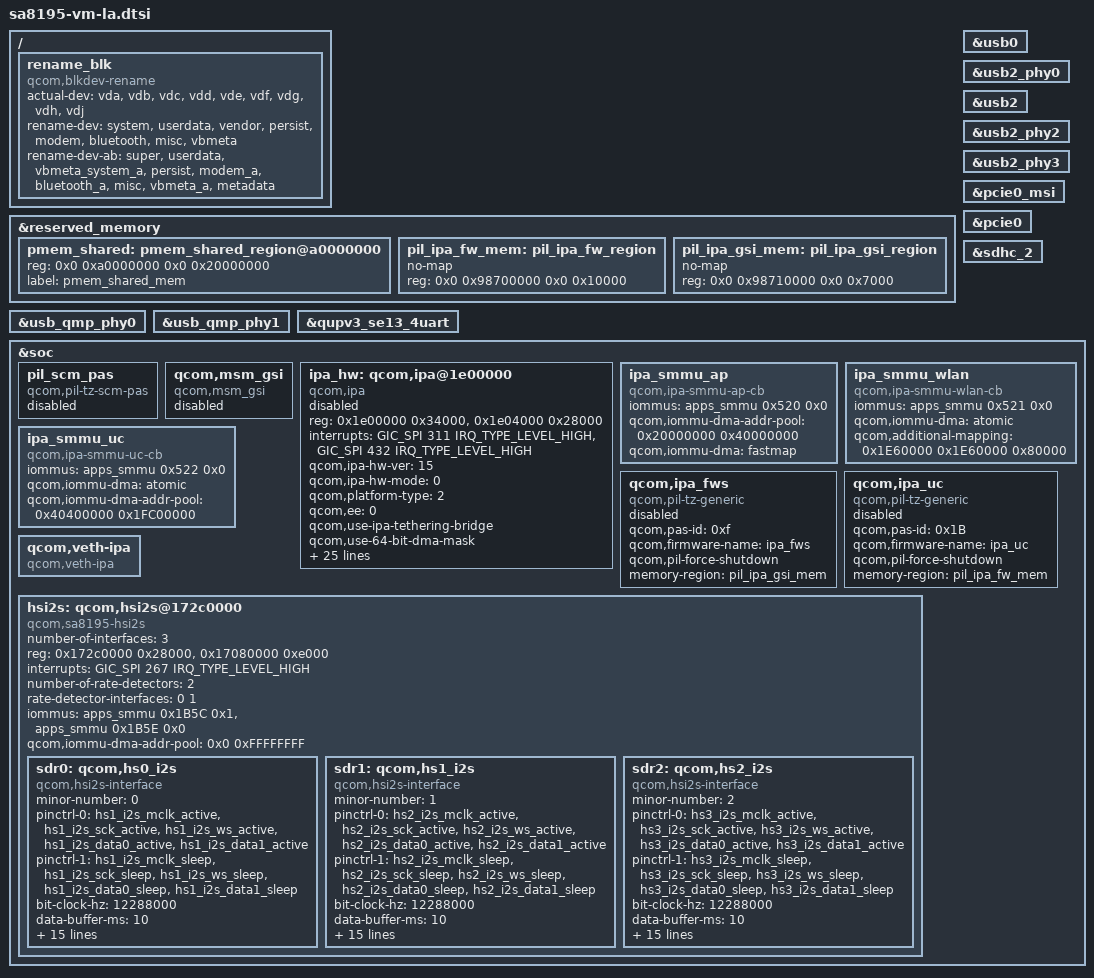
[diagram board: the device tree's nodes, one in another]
&reserved_memory {
	pmem_shared: pmem_shared_region@a0000000 {
		reg = <0x0 0xa0000000 0x0 0x20000000>;
		label = "pmem_shared_mem";
	};

	pil_ipa_fw_mem: pil_ipa_fw_region {
		no-map;
		reg = <0x0 0x98700000 0x0 0x10000>;
	};

	pil_ipa_gsi_mem: pil_ipa_gsi_region {
		no-map;
		reg = <0x0 0x98710000 0x0 0x7000>;
	};

};

/ {
	rename_blk: rename_blk {
		compatible = "qcom,blkdev-rename";
		actual-dev = "vda", "vdb", "vdc",
				"vdd", "vde", "vdf",
				"vdg", "vdh", "vdj";
		rename-dev = "system", "userdata", "vendor",
				"persist", "modem", "bluetooth",
				"misc", "vbmeta";
		rename-dev-ab = "super", "userdata", "vbmeta_system_a",
				"persist", "modem_a", "bluetooth_a",
				"misc", "vbmeta_a", "metadata";
	};
};

#include "display/quin-vm-display-la.dtsi"

&usb0 {
	status = "ok";
};

&usb2_phy0 {
	status = "ok";
};

&usb2 {
	status = "ok";
};

&usb2_phy2 {
	status = "ok";
};

&usb_qmp_phy0 {
	status = "ok";
};

&usb2_phy3 {
	status = "ok";
};

&usb_qmp_phy1 {
	status = "ok";
};

&qupv3_se13_4uart {
	status = "ok";
};

&pcie0_msi {
	status = "ok";
};

&pcie0 {
	status = "ok";
};

&sdhc_2 {
	status = "ok";
};
&soc {
	pil_scm_pas {
		compatible = "qcom,pil-tz-scm-pas";
		status = "disabled";
	};

	qcom,msm_gsi {
		compatible = "qcom,msm_gsi";
		status = "disabled";
	};

	ipa_hw: qcom,ipa@1e00000 {
		compatible = "qcom,ipa";
		reg = <0x1e00000 0x34000>,
			  <0x1e04000 0x28000>;
		reg-names = "ipa-base", "gsi-base";
		interrupts =
			<GIC_SPI 311 IRQ_TYPE_LEVEL_HIGH>,
			<GIC_SPI 432 IRQ_TYPE_LEVEL_HIGH>;
		interrupt-names = "ipa-irq", "gsi-irq";
		qcom,ipa-hw-ver = <15>; /* IPA core version = IPAv4.1 */
		qcom,ipa-hw-mode = <0>;
		qcom,platform-type = <2>; /* APQ platform */
		qcom,ee = <0>;
		qcom,use-ipa-tethering-bridge;
		qcom,use-64-bit-dma-mask;
		qcom,arm-smmu;
		qcom,use-ipa-pm;
		qcom,ipa-config-is-auto;
		qcom,bandwidth-vote-for-ipa;
		qcom,ipa-wdi3-over-gsi;
		qcom,manual-fw-load;
		qcom,lan-rx-napi;
		qcom,tx-wrapper-cache-max-size = <400>;
		qcom,tx-napi;
		qcom,max_num_smmu_cb = <3>;
		qcom,register-collection-on-crash;
		qcom,testbus-collection-on-crash;
		qcom,non-tn-collection-on-crash;
		qcom,interconnect,num-cases = <5>;
		qcom,interconnect,num-paths = <0>;
		interconnects = <>;
		/* No vote */
		qcom,no-vote = <>;

		/* SVS2 */
		qcom,svs2 = <>;

		/* SVS */
		qcom,svs = <>;

		/* NOMINAL */
		qcom,nominal = <>;

		/* TURBO */
		qcom,turbo = <>;

		qcom,bus-vector-names = "MIN", "SVS2", "SVS", "NOMINAL",
		"TURBO";
		qcom,throughput-threshold = <310 600 1000>;
		qcom,scaling-exceptions = <>;
		status = "disabled";
	};

	ipa_smmu_ap: ipa_smmu_ap {
		compatible = "qcom,ipa-smmu-ap-cb";
		iommus = <&apps_smmu 0x520 0x0>;
		qcom,iommu-dma-addr-pool = <0x20000000 0x40000000>;
		qcom,iommu-dma = "fastmap";
	};

	ipa_smmu_wlan: ipa_smmu_wlan {
		compatible = "qcom,ipa-smmu-wlan-cb";
		iommus = <&apps_smmu 0x521 0x0>;
		qcom,iommu-dma = "atomic";
		qcom,additional-mapping =
		/* ipa-uc ram */
		<0x1E60000 0x1E60000 0x80000>;
	};

	ipa_smmu_uc: ipa_smmu_uc {
		compatible = "qcom,ipa-smmu-uc-cb";
		iommus = <&apps_smmu 0x522 0x0>;
		qcom,iommu-dma = "atomic";
		qcom,iommu-dma-addr-pool = <0x40400000 0x1FC00000>;
	};

	qcom,ipa_fws {
		compatible = "qcom,pil-tz-generic";
		qcom,pas-id = <0xf>;
		qcom,firmware-name = "ipa_fws";
		qcom,pil-force-shutdown;
		memory-region = <&pil_ipa_gsi_mem>;
		status = "disabled";
	};

	qcom,ipa_uc {
		compatible = "qcom,pil-tz-generic";
		qcom,pas-id = <0x1B>;
		qcom,firmware-name = "ipa_uc";
		qcom,pil-force-shutdown;
		memory-region = <&pil_ipa_fw_mem>;
		status = "disabled";
	};

	qcom,veth-ipa {
		compatible = "qcom,veth-ipa";
	};

	hsi2s: qcom,hsi2s@172c0000 {
		compatible = "qcom,sa8195-hsi2s", "qcom,hsi2s";
		number-of-interfaces = <3>;
		reg = <0x172c0000 0x28000>,
		      <0x17080000 0xe000>;
		reg-names = "lpa_if", "lpass_tcsr";
		interrupts = <GIC_SPI 267 IRQ_TYPE_LEVEL_HIGH>;
		number-of-rate-detectors = <2>;
		rate-detector-interfaces = <0 1>;
		iommus = <&apps_smmu 0x1B5C 0x1>,
			 <&apps_smmu 0x1B5E 0x0>;
		qcom,iommu-dma-addr-pool = <0x0 0xFFFFFFFF>;

		sdr0: qcom,hs0_i2s {
			compatible = "qcom,hsi2s-interface";
			minor-number = <0>;
			pinctrl-names = "default", "sleep";
			pinctrl-0 = <&hs1_i2s_mclk_active &hs1_i2s_sck_active
				     &hs1_i2s_ws_active &hs1_i2s_data0_active
				     &hs1_i2s_data1_active>;
			pinctrl-1 = <&hs1_i2s_mclk_sleep &hs1_i2s_sck_sleep
				     &hs1_i2s_ws_sleep &hs1_i2s_data0_sleep
				     &hs1_i2s_data1_sleep>;
			bit-clock-hz = <12288000>;
			data-buffer-ms = <10>;
			bit-depth = <32>;
			spkr-channel-count = <2>;
			mic-channel-count = <2>;
			pcm-rate = <2>;
			pcm-sync-src = <0>;
			aux-mode = <0>;
			rpcm-width = <1>;
			tpcm-width = <1>;
			enable-tdm = <1>;
			tdm-rate = <32>;
			tdm-rpcm-width = <16>;
			tdm-tpcm-width = <16>;
			tdm-sync-delay = <2>;
			tdm-inv-sync = <0>;
			pcm-lane-config = <1>;
		};

		sdr1: qcom,hs1_i2s {
			compatible = "qcom,hsi2s-interface";
			minor-number = <1>;
			pinctrl-names = "default", "sleep";
			pinctrl-0 = <&hs2_i2s_mclk_active &hs2_i2s_sck_active
				     &hs2_i2s_ws_active &hs2_i2s_data0_active
				     &hs2_i2s_data1_active>;
			pinctrl-1 = <&hs2_i2s_mclk_sleep &hs2_i2s_sck_sleep
				     &hs2_i2s_ws_sleep &hs2_i2s_data0_sleep
				     &hs2_i2s_data1_sleep>;
			bit-clock-hz = <12288000>;
			data-buffer-ms = <10>;
			bit-depth = <32>;
			spkr-channel-count = <2>;
			mic-channel-count = <2>;
			pcm-rate = <2>;
			pcm-sync-src = <0>;
			aux-mode = <0>;
			rpcm-width = <1>;
			tpcm-width = <1>;
			enable-tdm = <1>;
			tdm-rate = <32>;
			tdm-rpcm-width = <16>;
			tdm-tpcm-width = <16>;
			tdm-sync-delay = <2>;
			tdm-inv-sync = <0>;
			pcm-lane-config = <1>;
		};

		sdr2: qcom,hs2_i2s {
			compatible = "qcom,hsi2s-interface";
			minor-number = <2>;
			pinctrl-names = "default", "sleep";
			pinctrl-0 = <&hs3_i2s_mclk_active &hs3_i2s_sck_active
				     &hs3_i2s_ws_active &hs3_i2s_data0_active
				     &hs3_i2s_data1_active>;
			pinctrl-1 = <&hs3_i2s_mclk_sleep &hs3_i2s_sck_sleep
				     &hs3_i2s_ws_sleep &hs3_i2s_data0_sleep
				     &hs3_i2s_data1_sleep>;
			bit-clock-hz = <12288000>;
			data-buffer-ms = <10>;
			bit-depth = <32>;
			spkr-channel-count = <2>;
			mic-channel-count = <2>;
			pcm-rate = <2>;
			pcm-sync-src = <0>;
			aux-mode = <0>;
			rpcm-width = <1>;
			tpcm-width = <1>;
			enable-tdm = <1>;
			tdm-rate = <32>;
			tdm-rpcm-width = <16>;
			tdm-tpcm-width = <16>;
			tdm-sync-delay = <2>;
			tdm-inv-sync = <0>;
			pcm-lane-config = <1>;
		};
	};
};
